# M46B register map
File version: 2.0.2.1
Registers are 32-bit, read-write, reset 0x0 unless marked. A register's access mark holds for its fields unless they carry their own. Offsets are from the block's base; [hi:lo] are bit positions; {n}, {i} and the like mark numbered series.

## AES — Advanced Encryption Standard (AES)
Base 0x400B8200
0x00 DT wo — Plaintext_encrypted text data Register
0x04 KEY7 — Input Key Data Register (bit 31 - 0)
  [31:0] KEY
0x08 KEY6 — Input Key Data Register (bit 63 - 32)
  [31:0] KEY
0x0C KEY5 — Input Key Data Register (bit 95 - 64)
  [31:0] KEY
0x10 KEY4 — Input Key Data Register (bit 127 - 96)
  [31:0] KEY
0x14 KEY3 — Input Key Data Register (bit 159 - 128)
  [31:0] KEY
0x18 KEY2 — Input Key Data Register (bit 191 - 160)
  [31:0] KEY
0x1C KEY1 — Input Key Data Register (bit 223 - 192)
  [31:0] KEY
0x20 KEY0 — Input Key Data Register (bit 255 - 224)
  [31:0] KEY
0x24 CNT3 — Counter Initial Value Register (bit 31 - 0)
  [31:0] CNT
0x28 CNT2 — Counter Initial Value Register (bit 63 - 32)
  [31:0] CNT
0x2C CNT1 — Counter Initial Value Register (bit 95 - 64)
  [31:0] CNT
0x30 CNT0 — Counter Initial Value Register (bit 127 - 96)
  [31:0] CNT
0x34 IV3 — Initial Vector Register (bit 31 - 0)
  [31:0] IV
0x38 IV2 — Initial Vector Register (bit 63 - 32)
  [31:0] IV
0x3C IV1 — Initial Vector Register (bit 95 - 64)
  [31:0] IV
0x40 IV0 — Initial Vector Register (bit 127 - 96)
  [31:0] IV
0x44 ODT ro — Calculation Result Store Register
0x48 RKEY7 ro — Output Key Store Register (bit 31 - 0)
  [31:0] RKEY
0x4C RKEY6 ro — Output Key Store Register (bit 63 - 32)
  [31:0] RKEY
0x50 RKEY5 ro — Output Key Store Register (bit 95 - 64)
  [31:0] RKEY
0x54 RKEY4 ro — Output Key Store Register (bit 127 - 96)
  [31:0] RKEY
0x58 RKEY3 ro — Output Key Store Register (bit 159 - 128)
  [31:0] RKEY
0x5C RKEY2 ro — Output Key Store Register (bit 191 - 160)
  [31:0] RKEY
0x60 RKEY1 ro — Output Key Store Register (bit 223 - 192)
  [31:0] RKEY
0x64 RKEY0 ro — Output Key Store Register (bit 255 - 224)
  [31:0] RKEY
0x68 CLR wo — FIFO Clear Register
  [0] FIFOCLR
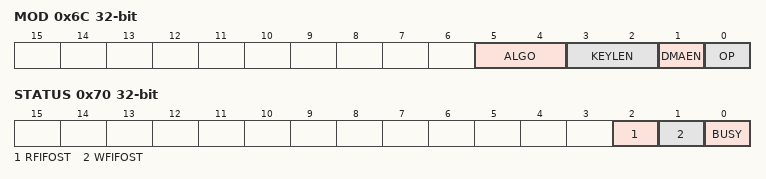
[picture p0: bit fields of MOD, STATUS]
0x6C MOD — Mode Setting Register
  [5:4] ALGO, [3:2] KEYLEN, [1] DMAEN, [0] OP
0x70 STATUS ro
  [2] RFIFOST, [1] WFIFOST, [0] BUSY

## SHA — Secure Hash Algorithm Processor (SHA)
Base 0x400B8300
0x00 START wo — Process Start Register
  [0] START
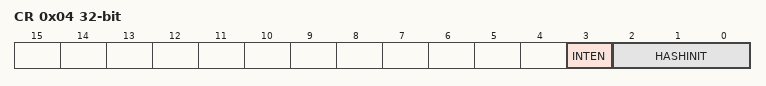
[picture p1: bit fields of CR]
0x04 CR — Control Register
  [3] INTEN, [2:0] HASHINIT
0x08 DMAEN — DMA Enable Register
  [0] DMAEN
0x0C MSGLEN0 — Whole Message Length Register (bit 31 - 0)
  [31:0] LEN
0x10 MSGLEN1 — Whole Message Length Register (bit 60 - 32)
  [28:0] LEN
0x14 REMAIN0 — Unhandled Message Length Register (bit 31 - 0)
  [31:0] REMAIN
0x18 REMAIN1 — Unhandled Message Length Register (bit 60 - 32)
  [28:0] REMAIN
{0x1C+4i} MSG{i:02} (i=0..15) — Message Register (bit {32i+31} - {32i})
  [31:0] MSG
{0x5C+4i} INIT{i} (i=0..7) — Hash Initial Value Register (bit {32i+31} - {32i})
  [31:0] INIT
{0x7C+4i} RESULT{i} ro (i=0..7) — Calculation Result Register (bit {32i+31} - {32i})
  [31:0] RESULT
0x9C STATUS ro
  [0] BUSY

## ESG — Entropy Seed Generator (ESG)
Base 0x400B8400
0x00 CR wo — Control Register
  [0] START
0x04 ST ro — Status Register
  [0] BUSY
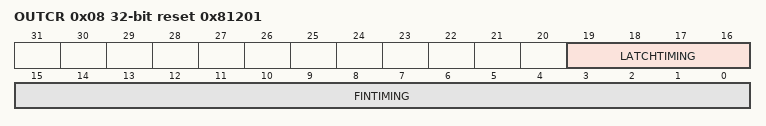
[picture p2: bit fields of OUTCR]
0x08 OUTCR reset 0x81201 — Output Control Register
  [19:16] LATCHTIMING, [15:0] FINTIMING
0x0C INT — Interrupt Status Register
  [0] INT
{0x10+4i} BLK{i:02} ro (i=0..15) — Entropy Seed Store Block {i:02}
  [31:0] BLK

## SRST — Soft Reset
Base 0x400B8500
0x00 SRSTPROTECT — Soft reset protect Register
  [7:0] PROTECT
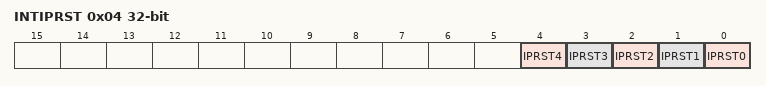
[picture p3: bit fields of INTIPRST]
0x04 INTIPRST — Soft reset Register
  [n] IPRST{n} (n=0..4)

## PA — Port A
Base 0x400C0000
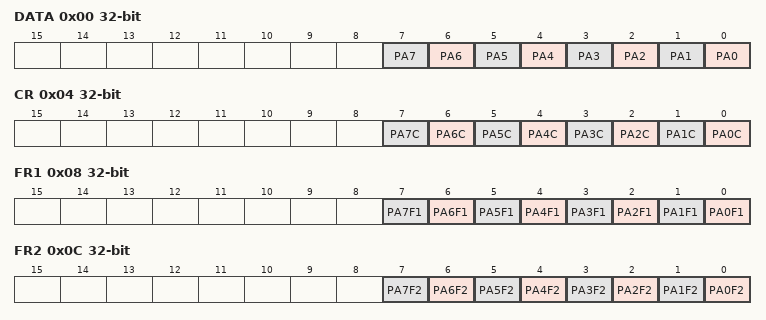
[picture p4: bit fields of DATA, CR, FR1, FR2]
0x00 DATA — Port A Data Register
  [n] PA{n} (n=0..7)
0x04 CR — Port A Output Control Register
  [n] PA{n}C (n=0..7)
0x08 FR1 — Port A Function Register 1
  [n] PA{n}F1 (n=0..7)
0x0C FR2 — Port A Function Register 2
  [n] PA{n}F2 (n=0..7)
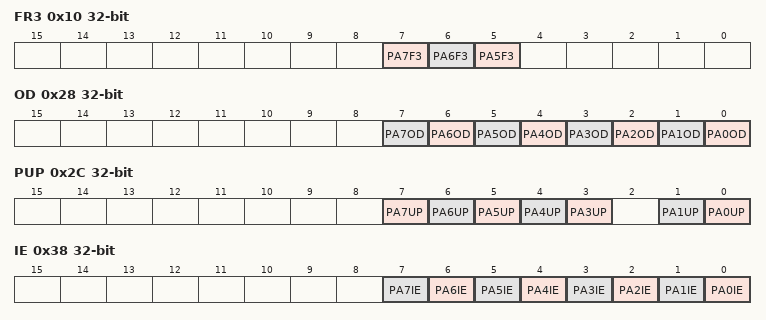
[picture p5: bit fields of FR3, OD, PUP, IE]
0x10 FR3 — Port A Function Register 3
  [7] PA7F3, [6] PA6F3, [5] PA5F3
0x14 FR4 — Port A Function Register 4
  [7] PA7F4
0x18 FR5 — Port A Function Register 5
  [7] PA7F5
0x28 OD — Port A Open Drain Control Register
  [n] PA{n}OD (n=0..7)
0x2C PUP — Port A Pull-up Control Register
  [n] PA{n}UP (n=3..7), [1] PA1UP, [0] PA0UP
0x30 PDN — Port A Pull-down Control Register
  [2] PA2DN
0x38 IE — Port A Input Control Register
  [n] PA{n}IE (n=0..7)
